# LPC1102 register map
File version: 3
Registers are 32-bit, read-write, reset 0x0 unless marked. A register's access mark holds for its fields unless they carry their own. Offsets are from the block's base; [hi:lo] are bit positions; {n}, {i} and the like mark numbered series; 'fields as' and 'values as' point back to an identical list.

## UART — Product name title=UM10429 Chapter title=LPC1102 Universal Asynchronous Transmitter (UART) Modification date=11/1/2010 Major revision=1 Minor revision=not available
Base 0x40008000
0x00 RBR ro reset not defined — Receiver Buffer Register. Contains the next received character to be read. (DLAB=0)
  [7:0] RBR — The UART Receiver Buffer Register contains the oldest received byte in the UART RX FIFO.
0x00 THR wo reset not defined (alternate view of RBR) — Transmit Holding Register. The next character to be transmitted is written here. (DLAB=0)
  [7:0] THR — Writing to the UART Transmit Holding Register causes the data to be stored in the UART transmit FIFO. The byte will be sent when it reaches the bottom of the FIFO and the transmitter is available.
0x00 DLL reset 0x1 (alternate view of RBR) — Divisor Latch LSB. Least significant byte of the baud rate divisor value. The full divisor is used to generate a baud rate from the fractional rate divider. (DLAB=1)
  [7:0] DLLSB — The UART Divisor Latch LSB Register, along with the DLM register, determines the baud rate of the UART.
0x04 DLM — Divisor Latch MSB. Most significant byte of the baud rate divisor value. The full divisor is used to generate a baud rate from the fractional rate divider. (DLAB=1)
  [7:0] DLMSB — The UART Divisor Latch MSB Register, along with the DLL register, determines the baud rate of the UART.
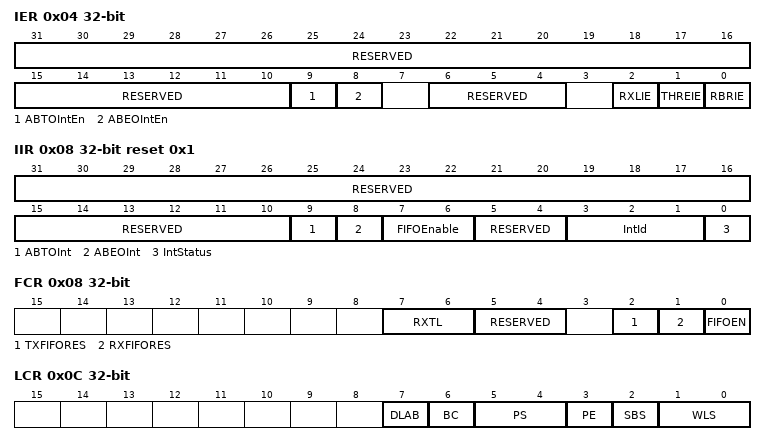
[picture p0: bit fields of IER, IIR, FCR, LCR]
0x04 IER (alternate view of DLM) — Interrupt Enable Register. Contains individual interrupt enable bits for the 7 potential UART interrupts. (DLAB=0)
  [31:10] RESERVED — Reserved, user software should not write ones to reserved bits. The value read from a reserved bit is not defined.
  [9] ABTOIntEn — Enables the auto-baud time-out interrupt.
    0=Disable auto-baud time-out Interrupt; 1=Enable auto-baud time-out Interrupt
  [8] ABEOIntEn — Enables the end of auto-baud interrupt.
    0=Disable end of auto-baud Interrupt; 1=Enable end of auto-baud Interrupt
  [6:4] RESERVED — Reserved, user software should not write ones to reserved bits. The value read from a reserved bit is not defined.
  [2] RXLIE — RX Line Interrupt Enable Enables the UART RX line status interrupts. The status of this interrupt can be read from LSR[4:1].
    0=Disable the RX line status interrupts; 1=Enable the RX line status interrupts
  [1] THREIE — THRE Interrupt Enable Enables the THRE interrupt for UART. The status of this interrupt can be read from LSR[5].
    0=Disable the THRE interrupt; 1=Enable the THRE interrupt
  [0] RBRIE — RBR Interrupt Enable Enables the Receive Data Available interrupt for UART. It also controls the Character Receive Time-out interrupt.
    0=Disable the RDA interrupt; 1=Enable the RDA interrupt
0x08 IIR ro reset 0x1 — Interrupt ID Register. Identifies which interrupt(s) are pending.
  [31:10] RESERVED — Reserved, user software should not write ones to reserved bits. The value read from a reserved bit is not defined.
  [9] ABTOInt — Auto-baud time-out interrupt. True if auto-baud has timed out and interrupt is enabled.
  [8] ABEOInt — End of auto-baud interrupt. True if auto-baud has finished successfully and interrupt is enabled.
  [7:6] FIFOEnable — These bits are equivalent to FCR[0].
  [5:4] RESERVED — Reserved, user software should not write ones to reserved bits. The value read from a reserved bit is not defined.
  [3:1] IntId — Interrupt identification. IER[3:1] identifies an interrupt corresponding to the UART Rx FIFO. All other combinations of IER[3:1] not listed below are reserved (000, 100,101,111).
    3=1   - Receive Line Status (RLS); 2=2a - Receive Data Available (RDA); 6=2b - Character Time-out Indicator (CTI); 1=3   - THRE Interrupt
  [0] IntStatus — Interrupt status. Note that IIR[0] is active low. The pending interrupt can be determined by evaluating IIR[3:1].
    0=At least one interrupt is pending; 1=No interrupt is pending
0x08 FCR wo (alternate view of IIR) — FIFO Control Register. Controls UART FIFO usage and modes.
  [7:6] RXTL — RX Trigger Level These two bits determine how many receiver UART FIFO characters must be written before an interrupt is activated.
    0=Trigger level 0 (1 character or 0x01); 1=Trigger level 1 (4 characters or 0x04); 2=Trigger level 2 (8 characters or 0x08); 3=Trigger level 3 (14 characters or 0x0E)
  [5:4] RESERVED — Reserved, user software should not write ones to reserved bits. The value read from a reserved bit is not defined.
  [2] TXFIFORES — TX FIFO Reset
    0=No impact on either of UART FIFOs; 1=Writing a logic 1 to FCR[2] will clear all bytes in UART TX FIFO, reset the pointer logic. This bit is self-clearing.
  [1] RXFIFORES — RX FIFO Reset
    0=No impact on either of UART FIFOs; 1=Writing a logic 1 to FCR[1] will clear all bytes in UART Rx FIFO, reset the pointer logic. This bit is self-clearing.
  [0] FIFOEN — FIFO Enable
    0=UART FIFOs are disabled. Must not be used in the application.; 1=Active high enable for both UART Rx and TX FIFOs and FCR[7:1] access. This bit must be set for proper UART operation. Any transition on this bit will automatically clear the UART FIFOs.
0x0C LCR — Line Control Register. Contains controls for frame formatting and break generation.
  [7] DLAB — Divisor Latch Access Bit (DLAB)
    0=Disable access to Divisor Latches; 1=Enable access to Divisor Latches
  [6] BC — Break Control
    0=Disable break transmission; 1=Enable break transmission. Output pin UART TXD is forced to logic 0 when LCR[6] is active high.
  [5:4] PS — Parity Select
    0=Odd parity. Number of 1s in the transmitted character and the attached parity bit will be odd.; 1=Even Parity. Number of 1s in the transmitted character and the attached parity bit will be even.; 2=Forced 1 stick parity; 3=Forced 0 stick parity
  [3] PE — Parity Enable
    0=Disable parity generation and checking; 1=Enable parity generation and checking
  [2] SBS — Stop Bit Select
    0=1 stop bit; 1=2 stop bits (1.5 if LCR[1:0]=00)
  [1:0] WLS — Word Length Select
    {v}={v+5}-bit character length (v=0..3)
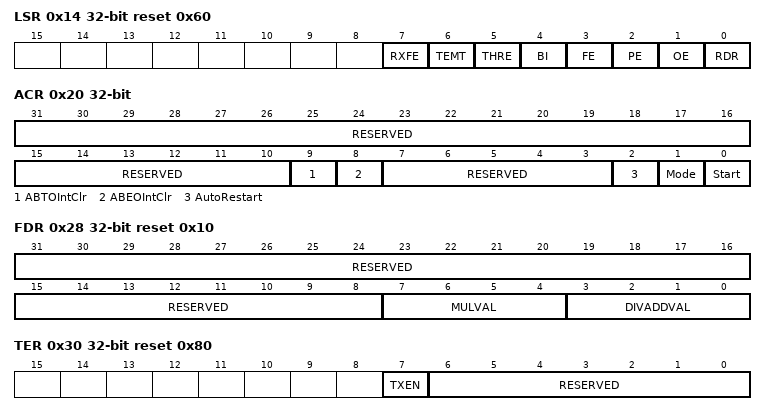
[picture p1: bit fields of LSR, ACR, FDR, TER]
0x14 LSR ro reset 0x60 — Line Status Register. Contains flags for transmit and receive status, including line errors.
  [7] RXFE — Error in RX FIFO LSR[7] is set when a character with a RX error such as framing error, parity error or break interrupt, is loaded into the RBR. This bit is cleared when the LSR register is read and there are no subsequent errors in the UART FIFO.
    0=RBR contains no UART RX errors or FCR[0]=0; 1=UART RBR contains at least one UART RX error
  [6] TEMT — Transmitter Empty TEMT is set when both THR and TSR are empty; TEMT is cleared when either the TSR or the THR contain valid data.
    0=THR and/or the TSR contains valid data; 1=THR and the TSR are empty
  [5] THRE — Transmitter Holding Register Empty THRE is set immediately upon detection of an empty UART THR and is cleared on a THR write.
    0=THR contains valid data; 1=THR is empty
  [4] BI — Break Interrupt When RXD1 is held in the spacing state (all zeros) for one full character transmission (start, data, parity, stop), a break interrupt occurs. Once the break condition has been detected, the receiver goes idle until RXD1 goes to marking state (all ones). A LSR read clears this status bit. The time of break detection is dependent on FCR[0]. Note: The break interrupt is associated with the character at the top of the UART RBR FIFO.
    0=Break interrupt status is inactive; 1=Break interrupt status is active
  [3] FE — Framing Error When the stop bit of a received character is a logic 0, a framing error occurs. A LSR read clears LSR[3]. The time of the framing error detection is dependent on FCR0. Upon detection of a framing error, the RX will attempt to re-synchronize to the data and assume that the bad stop bit is actually an early start bit. However, it cannot be assumed that the next received byte will be correct even if there is no Framing Error. Note: A framing error is associated with the character at the top of the UART RBR FIFO.
    0=Framing error status is inactive; 1=Framing error status is active
  [2] PE — Parity Error When the parity bit of a received character is in the wrong state, a parity error occurs. A LSR read clears LSR[2]. Time of parity error detection is dependent on FCR[0]. Note: A parity error is associated with the character at the top of the UART RBR FIFO.
    0=Parity error status is inactive; 1=Parity error status is active
  [1] OE — Overrun Error The overrun error condition is set as soon as it occurs. A LSR read clears LSR[1]. LSR[1] is set when UART RSR has a new character assembled and the UART RBR FIFO is full. In this case, the UART RBR FIFO will not be overwritten and the character in the UART RSR will be lost.
    0=Overrun error status is inactive; 1=Overrun error status is active
  [0] RDR — Receiver Data Ready:LSR[0] is set when the RBR holds an unread character and is cleared when the UART RBR FIFO is empty.
    0=RBR is empty; 1=RBR contains valid data
0x1C SCR — Scratch Pad Register. Eight-bit temporary storage for software.
  [7:0] Pad — A readable, writable byte.
0x20 ACR — Auto-baud Control Register. Contains controls for the auto-baud feature.
  [31:10] RESERVED — Reserved, user software should not write ones to reserved bits. The value read from a reserved bit is not defined.
  [9] ABTOIntClr — Auto-baud time-out interrupt clear bit (write only accessible).
    0=Writing a 0 has no impact; 1=Writing a 1 will clear the corresponding interrupt in the IIR
  [8] ABEOIntClr — End of auto-baud interrupt clear bit (write only accessible).
    values as ABTOIntClr
  [7:3] RESERVED — Reserved, user software should not write ones to reserved bits. The value read from a reserved bit is not defined.
  [2] AutoRestart — Restart select.
    0=No restart; 1=Restart in case of time-out (counter restarts at next UART Rx falling edge)
  [1] Mode — Auto-baud mode select bit.
    0=Mode 0; 1=Mode 1
  [0] Start — This bit is automatically cleared after auto-baud completion.
    0=Auto-baud stop (auto-baud is not running); 1=Auto-baud start (auto-baud is running). Auto-baud run bit. This bit is automatically cleared after auto-baud completion.
0x28 FDR reset 0x10 — Fractional Divider Register. Generates a clock input for the baud rate divider.
  [31:8] RESERVED — Reserved, user software should not write ones to reserved bits. The value read from a reserved bit is not defined.
  [7:4] MULVAL — Baud rate pre-scaler multiplier value. This field must be greater or equal 1 for UART to operate properly, regardless of whether the fractional baud rate generator is used or not.
  [3:0] DIVADDVAL — Baud rate generation pre-scaler divisor value. If this field is 0, fractional baud rate generator will not impact the UART baud rate.
0x30 TER reset 0x80 — Transmit Enable Register. Turns off UART transmitter for use with software flow control.
  [7] TXEN — When this bit is 1, as it is after a Reset, data written to the THR is output on the TXD pin as soon as any preceding data has been sent. If this bit cleared to 0 while a character is being sent, the transmission of that character is completed, but no further characters are sent until this bit is set again. In other words, a 0 in this bit blocks the transfer of characters from the THR or TX FIFO into the transmit shift register. Software can clear this bit when it detects that the a hardware-handshaking TX-permit signal (CTS) has gone false, or with software handshaking, when it receives an XOFF character (DC3). Software can set this bit again when it detects that the TX-permit signal has gone true, or when it receives an XON (DC1) character.
  [6:0] RESERVED — Reserved, user software should not write ones to reserved bits. The value read from a reserved bit is not defined.
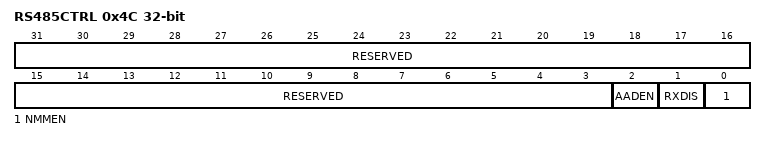
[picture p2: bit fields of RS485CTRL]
0x4C RS485CTRL — RS-485/EIA-485 Control. Contains controls to configure various aspects of RS-485/EIA-485 modes.
  [31:3] RESERVED — Reserved, user software should not write ones to reserved bits. The value read from a reserved bit is not defined.
  [2] AADEN — Auto Address Detect (AAD) enable/disable
    0=Auto Address Detect (AAD) is disabled; 1=Auto Address Detect (AAD) is enabled
  [1] RXDIS — Receiver enable/disable
    0=The receiver is enabled; 1=The receiver is disabled
  [0] NMMEN — RS-485/EIA-485 mode
    0=RS-485/EIA-485 Normal Multidrop Mode (NMM) is disabled; 1=RS-485/EIA-485 Normal Multidrop Mode (NMM) is enabled. In this mode, an address is detected when a received byte causes the UART to set the parity error and generate an interrupt.
0x50 RS485ADRMATCH — RS-485/EIA-485 address match. Contains the address match value for RS-485/EIA-485 mode.
  [7:0] ADRMATCH — Contains the address match value.
